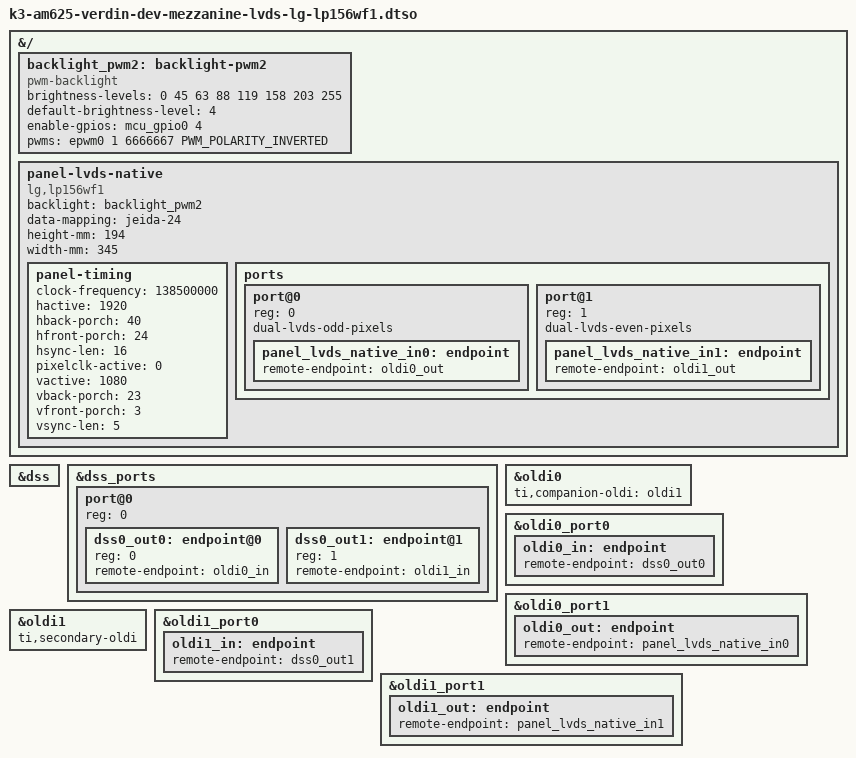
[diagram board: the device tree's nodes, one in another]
// SPDX-License-Identifier: GPL-2.0-or-later OR MIT
/*
 * Copyright (c) Toradex
 *
 * LG LP156WF1 dual-channel LVDS panel on Verdin AM62 Mezzanine
 * LVDS interface (J10), used with the Verdin Development Board.
 */

/dts-v1/;
/plugin/;

#include <dt-bindings/gpio/gpio.h>
#include <dt-bindings/pwm/pwm.h>

&{/} {
	backlight_pwm2: backlight-pwm2 {
		compatible = "pwm-backlight";
		brightness-levels = <0 45 63 88 119 158 203 255>;
		default-brightness-level = <4>;
		/* Verdin GPIO_4 (SODIMM 212) - LVDS_BKL_EN */
		enable-gpios = <&mcu_gpio0 4 GPIO_ACTIVE_HIGH>;
		/* Verdin PWM_2 (SODIMM 16) - LVDS_PWM */
		pwms = <&epwm0 1 6666667 PWM_POLARITY_INVERTED>;
	};

	panel-lvds-native {
		compatible = "lg,lp156wf1", "panel-lvds";
		backlight = <&backlight_pwm2>;
		data-mapping = "jeida-24";
		height-mm = <194>;
		width-mm = <345>;

		panel-timing {
			clock-frequency = <138500000>;
			hactive = <1920>;
			hback-porch = <40>;
			hfront-porch = <24>;
			hsync-len = <16>;
			pixelclk-active = <0>;
			vactive = <1080>;
			vback-porch = <23>;
			vfront-porch = <3>;
			vsync-len = <5>;
		};

		ports {
			#address-cells = <1>;
			#size-cells = <0>;

			port@0 {
				reg = <0>;
				dual-lvds-odd-pixels;

				panel_lvds_native_in0: endpoint {
					remote-endpoint = <&oldi0_out>;
				};
			};

			port@1 {
				reg = <1>;
				dual-lvds-even-pixels;

				panel_lvds_native_in1: endpoint {
					remote-endpoint = <&oldi1_out>;
				};
			};
		};
	};
};

&dss {
	status = "okay";
};

&dss_ports {
	#address-cells = <1>;
	#size-cells = <0>;

	/* DSS VP1: internal DPI output to OLDIx */
	port@0 {
		reg = <0>;
		#address-cells = <1>;
		#size-cells = <0>;

		dss0_out0: endpoint@0 {
			reg = <0>;
			remote-endpoint = <&oldi0_in>;
		};

		dss0_out1: endpoint@1 {
			reg = <1>;
			remote-endpoint = <&oldi1_in>;
		};
	};
};

&oldi0 {
	ti,companion-oldi = <&oldi1>;
	status = "okay";
};

&oldi0_port0 {
	oldi0_in: endpoint {
		remote-endpoint = <&dss0_out0>;
	};
};

&oldi0_port1 {
	oldi0_out: endpoint {
		remote-endpoint = <&panel_lvds_native_in0>;
	};
};

&oldi1 {
	ti,secondary-oldi;
	status = "okay";
};

&oldi1_port0 {
	oldi1_in: endpoint {
		remote-endpoint = <&dss0_out1>;
	};
};

&oldi1_port1 {
	oldi1_out: endpoint {
		remote-endpoint = <&panel_lvds_native_in1>;
	};
};
